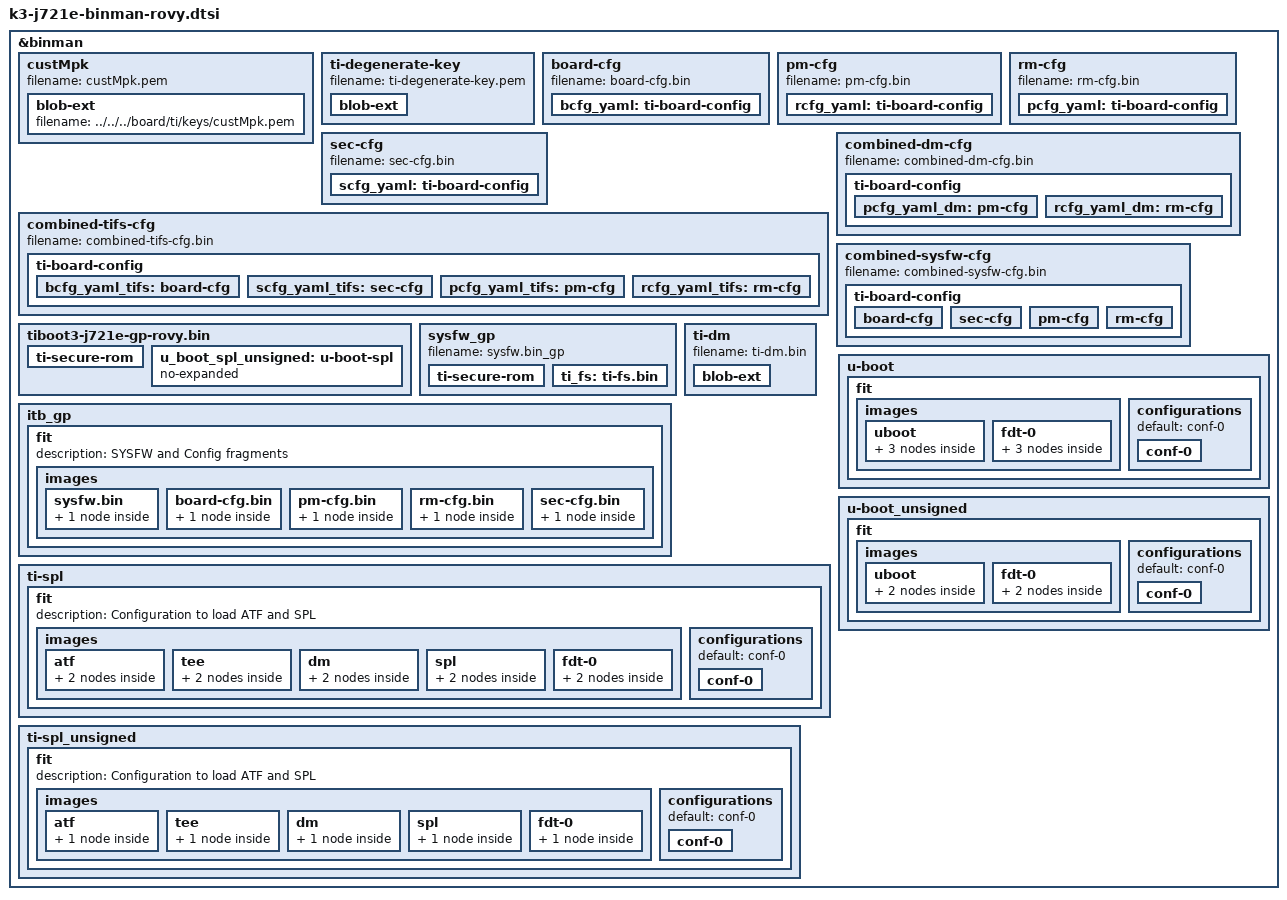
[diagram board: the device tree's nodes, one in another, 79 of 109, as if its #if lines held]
// SPDX-License-Identifier: GPL-2.0
/*
 * Copyright (C) 2022 Texas Instruments Incorporated - https://www.ti.com/
 */

#include "k3-binman.dtsi"

&binman {
	custMpk {
		filename = "custMpk.pem";
		blob-ext {
			filename = "../../../board/ti/keys/custMpk.pem";
		};
	};
	ti-degenerate-key {
		filename = "ti-degenerate-key.pem";
		blob-ext {
			filename = "../../../board/ti/keys/ti-degenerate-key.pem";
		};
	};
};
#ifdef CONFIG_TARGET_ROVY_4VM_R5
&binman {
	board-cfg {
		filename = "board-cfg.bin";
		bcfg_yaml: ti-board-config {
			config = "../../../board/ti/j721e/board-cfg.yaml";
			schema = "../../../board/ti/common/schema.yaml";
		};
	};
	pm-cfg {
		filename = "pm-cfg.bin";
		rcfg_yaml: ti-board-config {
			config = "../../../board/ti/j721e/pm-cfg.yaml";
			schema = "../../../board/ti/common/schema.yaml";
		};
	};
	rm-cfg {
		filename = "rm-cfg.bin";
		pcfg_yaml: ti-board-config {
			config = "../../../board/ti/j721e/rm-cfg.yaml";
			schema = "../../../board/ti/common/schema.yaml";
		};
	};
	sec-cfg {
		filename = "sec-cfg.bin";
		scfg_yaml: ti-board-config {
			config = "../../../board/ti/j721e/sec-cfg.yaml";
			schema = "../../../board/ti/common/schema.yaml";
		};
	};
	combined-tifs-cfg {
		filename = "combined-tifs-cfg.bin";
		ti-board-config {
			bcfg_yaml_tifs: board-cfg {
				config = "../../../board/ti/j721e/board-cfg.yaml";
				schema = "../../../board/ti/common/schema.yaml";
			};
			scfg_yaml_tifs: sec-cfg {
				config = "../../../board/ti/j721e/sec-cfg.yaml";
				schema = "../../../board/ti/common/schema.yaml";
			};
			pcfg_yaml_tifs: pm-cfg {
				config = "../../../board/ti/j721e/pm-cfg.yaml";
				schema = "../../../board/ti/common/schema.yaml";
			};
			rcfg_yaml_tifs: rm-cfg {
				config = "../../../board/ti/j721e/rm-cfg.yaml";
				schema = "../../../board/ti/common/schema.yaml";
			};
		};
	};
	combined-dm-cfg {
		filename = "combined-dm-cfg.bin";
		ti-board-config {
			pcfg_yaml_dm: pm-cfg {
				config = "../../../board/ti/j721e/pm-cfg.yaml";
				schema = "../../../board/ti/common/schema.yaml";
			};
			rcfg_yaml_dm: rm-cfg {
				config = "../../../board/ti/j721e/rm-cfg.yaml";
				schema = "../../../board/ti/common/schema.yaml";
			};
		};
	};
	combined-sysfw-cfg {
		filename = "combined-sysfw-cfg.bin";
		ti-board-config {
			board-cfg {
				config = "../../../board/ti/j721e/board-cfg.yaml";
				schema = "../../../board/ti/common/schema.yaml";
			};
			sec-cfg {
				config = "../../../board/ti/j721e/sec-cfg.yaml";
				schema = "../../../board/ti/common/schema.yaml";
			};
			pm-cfg {
				config = "../../../board/ti/j721e/pm-cfg.yaml";
				schema = "../../../board/ti/common/schema.yaml";
			};
			rm-cfg {
				config = "../../../board/ti/j721e/rm-cfg.yaml";
				schema = "../../../board/ti/common/schema.yaml";
			};
		};
	};
	tiboot3-j721e-gp-rovy.bin {
		filename = "tiboot3-j721e-gp-rovy.bin";
		symlink = "tiboot3.bin";
		ti-secure-rom {
			content = <&u_boot_spl_unsigned>;
			core = "public";
			load = <CONFIG_SPL_TEXT_BASE>;
			sw-rev = <CONFIG_K3_X509_SWRV>;
			keyfile = "ti-degenerate-key.pem";
		};
		u_boot_spl_unsigned: u-boot-spl {
			no-expanded;
		};
	};
	sysfw_gp {
		filename = "sysfw.bin_gp";
		ti-secure-rom {
			content = <&ti_fs>;
			core = "secure";
			load = <0x40000>;
			sw-rev = <CONFIG_K3_X509_SWRV>;
			keyfile = "ti-degenerate-key.pem";
		};
		ti_fs: ti-fs.bin {
			filename = "ti-sysfw/ti-fs-firmware-j721e-gp.bin";
			type = "blob-ext";
			optional;
		};
	};
	itb_gp {
		filename = "sysfw-j721e-gp-rovy.itb";
		symlink = "sysfw.itb";
		fit {
			description = "SYSFW and Config fragments";
			#address-cells = <1>;
			images {
				sysfw.bin {
					description = "sysfw";
					type = "firmware";
					arch = "arm";
					compression = "none";
					blob-ext {
					    filename = "sysfw.bin_gp";
					};
				};
				board-cfg.bin {
					description = "board-cfg";
					type = "firmware";
					arch = "arm";
					compression = "none";
					blob-ext {
						filename = "board-cfg.bin";
					};
				};
				pm-cfg.bin {
					description = "pm-cfg";
					type = "firmware";
					arch = "arm";
					compression = "none";
					blob-ext {
						filename = "pm-cfg.bin";
					};
				};
				rm-cfg.bin {
					description = "rm-cfg";
					type = "firmware";
					arch = "arm";
					compression = "none";
					blob-ext {
						filename = "rm-cfg.bin";
					};
				};
				sec-cfg.bin {
					description = "sec-cfg";
					type = "firmware";
					arch = "arm";
					compression = "none";
					blob-ext {
						filename = "sec-cfg.bin";
					};
				};
			};
		};
	};
};
#endif

#ifdef CONFIG_TARGET_ROVY_4VM_A72

#define SPL_NODTB "spl/u-boot-spl-nodtb.bin"
#define SPL_J721E_ROVY_DTB "spl/dts/k3-j721e-rovy-evm.dtb"

#define UBOOT_NODTB "u-boot-nodtb.bin"
#define J721E_ROVY_DTB "arch/arm/dts/k3-j721e-rovy-evm.dtb"

/* Signed tispl.bin */
&binman {
	ti-dm {
		filename = "ti-dm.bin";
		blob-ext {
			filename = "ti-dm/j721e/ipc_echo_testb_mcu1_0_release_strip.xer5f";
		};
	};
	ti-spl {
		filename = "tispl.bin";
		pad-byte = <0xff>;

		fit {
			description = "Configuration to load ATF and SPL";
			#address-cells = <1>;

			images {

				atf {
					description = "ARM Trusted Firmware";
					type = "firmware";
					arch = "arm64";
					compression = "none";
					os = "arm-trusted-firmware";
					load = <CONFIG_K3_ATF_LOAD_ADDR>;
					entry = <CONFIG_K3_ATF_LOAD_ADDR>;
					ti-secure {
						content = <&atf>;
						keyfile = "custMpk.pem";
					};
					atf: atf-bl31 {
					};
				};

				tee {
					description = "OPTEE";
					type = "tee";
					arch = "arm64";
					compression = "none";
					os = "tee";
					load = <0x9e800000>;
					entry = <0x9e800000>;
					ti-secure {
						content = <&tee>;
						keyfile = "custMpk.pem";
					};
					tee: tee-os {
					};
				};

				dm {
					description = "DM binary";
					type = "firmware";
					arch = "arm32";
					compression = "none";
					os = "DM";
					load = <0x89000000>;
					entry = <0x89000000>;
					ti-secure {
						content = <&dm>;
						keyfile = "custMpk.pem";
					};
					dm: blob-ext {
						filename = "ti-dm.bin";
					};
				};

				spl {
					description = "SPL (64-bit)";
					type = "standalone";
					os = "U-Boot";
					arch = "arm64";
					compression = "none";
					load = <CONFIG_SPL_TEXT_BASE>;
					entry = <CONFIG_SPL_TEXT_BASE>;
					ti-secure {
						content = <&u_boot_spl_nodtb>;
						keyfile = "custMpk.pem";

					};
					u_boot_spl_nodtb: blob-ext {
						filename = SPL_NODTB;
					};
				};

				fdt-0 {
					description = "k3-j721e-rovy-evm";
					type = "flat_dt";
					arch = "arm";
					compression = "none";
					ti-secure {
						content = <&spl_j721e_rovy_dtb>;
						keyfile = "custMpk.pem";
					};
					spl_j721e_rovy_dtb: blob-ext {
						filename = SPL_J721E_ROVY_DTB;
					};
				};
			};

			configurations {
				default = "conf-0";

				conf-0 {
					description = "k3-j721e-rovy-evm";
					firmware = "atf";
					loadables = "tee", "dm", "spl";
					fdt = "fdt-0";
				};
			};
		};
	};
};

/* Unsigned tispl.bin */
&binman {
	ti-spl_unsigned {
		filename = "tispl.bin_unsigned";
		pad-byte = <0xff>;

		fit {
			description = "Configuration to load ATF and SPL";
			#address-cells = <1>;

			images {

				atf {
					description = "ARM Trusted Firmware";
					type = "firmware";
					arch = "arm64";
					compression = "none";
					os = "arm-trusted-firmware";
					load = <CONFIG_K3_ATF_LOAD_ADDR>;
					entry = <CONFIG_K3_ATF_LOAD_ADDR>;
					atf-bl31 {
						filename = "bl31.bin";
					};
				};

				tee {
					description = "OPTEE";
					type = "tee";
					arch = "arm64";
					compression = "none";
					os = "tee";
					load = <0x9e800000>;
					entry = <0x9e800000>;
					tee-os {
						filename = "tee-pager_v2.bin";
					};
				};

				dm {
					description = "DM binary";
					type = "firmware";
					arch = "arm32";
					compression = "none";
					os = "DM";
					load = <0x89000000>;
					entry = <0x89000000>;
					blob-ext {
						filename = "ti-dm.bin";
					};
				};

				spl {
					description = "SPL (64-bit)";
					type = "standalone";
					os = "U-Boot";
					arch = "arm64";
					compression = "none";
					load = <CONFIG_SPL_TEXT_BASE>;
					entry = <CONFIG_SPL_TEXT_BASE>;
					blob-ext {
						filename = SPL_NODTB;
					};
				};

				fdt-0 {
					description = "k3-j721e-rovy-evm";
					type = "flat_dt";
					arch = "arm";
					compression = "none";
					spl_j721e_rovy_dtb_unsigned: blob {
						filename = SPL_J721E_ROVY_DTB;
					};
				};
			};

			configurations {
				default = "conf-0";

				conf-0 {
					description = "k3-j721e-rovy-evm";
					firmware = "atf";
					loadables = "tee", "dm", "spl";
					fdt = "fdt-0";
				};
			};
		};
	};
};

/* Signed u-boot.img */
&binman {
	u-boot {
		filename = "u-boot.img";
		pad-byte = <0xff>;

		fit {
			description = "FIT image with multiple configurations";

			images {
				uboot {
					description = "U-Boot for j721e board";
					type = "firmware";
					os = "u-boot";
					arch = "arm";
					compression = "none";
					load = <CONFIG_TEXT_BASE>;
					ti-secure {
						content = <&u_boot_nodtb>;
						keyfile = "custMpk.pem";
					};
					u_boot_nodtb: u-boot-nodtb {
					};
					hash {
						algo = "crc32";
					};
				};

				fdt-0 {
					description = "k3-j721e-rovy-evm";
					type = "flat_dt";
					arch = "arm";
					compression = "none";
					ti-secure {
						content = <&j721e_rovy_dtb>;
						keyfile = "custMpk.pem";

					};
					j721e_rovy_dtb: blob-ext {
						filename = J721E_ROVY_DTB;
					};
					hash {
						algo = "crc32";
					};
				};
			};

			configurations {
				default = "conf-0";

				conf-0 {
					description = "k3-j721e-rovy-evm";
					firmware = "uboot";
					loadables = "uboot";
					fdt = "fdt-0";
				};
			};
		};
	};
};

/* Unsigned u-boot.img */
&binman {
	u-boot_unsigned {
		filename = "u-boot.img_unsigned";
		pad-byte = <0xff>;

		fit {
			description = "FIT image with multiple configurations";

			images {
				uboot {
					description = "U-Boot for j721e board";
					type = "firmware";
					os = "u-boot";
					arch = "arm";
					compression = "none";
					load = <CONFIG_TEXT_BASE>;
					blob {
						filename = UBOOT_NODTB;
					};
					hash {
						algo = "crc32";
					};
				};

				fdt-0 {
					description = "k3-j721e-rovy-evm";
					type = "flat_dt";
					arch = "arm";
					compression = "none";
					j721e_rovy_dtb_unsigned: blob {
						filename = J721E_ROVY_DTB;
					};
					hash {
						algo = "crc32";
					};
				};
			};

			configurations {
				default = "conf-0";

				conf-0 {
					description = "k3-j721e-rovy-evm";
					firmware = "uboot";
					loadables = "uboot";
					fdt = "fdt-0";
				};
			};
		};
	};
};
#endif
